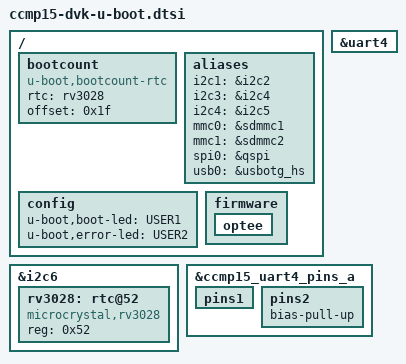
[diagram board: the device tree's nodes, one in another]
// SPDX-License-Identifier: GPL-2.0+ OR BSD-3-Clause
/*
 * Copyright (C) 2023-2025, Digi International Inc - All Rights Reserved
 */

#include "stm32mp15-u-boot.dtsi"

/ {
	bootcount {
		compatible = "u-boot,bootcount-rtc";
		rtc = <&rv3028>;
		offset = <0x1f>;
	};

	aliases {
		i2c1 = &i2c2;
		i2c3 = &i2c4;
		i2c4 = &i2c5;
		mmc0 = &sdmmc1;
		mmc1 = &sdmmc2;
		spi0 = &qspi;
		usb0 = &usbotg_hs;
	};

	config {
		u-boot,boot-led = "USER1";
		u-boot,error-led = "USER2";
	};

	firmware {
		optee {
			bootph-all;
		};
	};
};

&i2c6 {
	rv3028: rtc@52 {
		compatible = "microcrystal,rv3028";
		reg = <0x52>;
	};
};

&uart4 {
	bootph-all;
};

&ccmp15_uart4_pins_a {
	bootph-all;
	pins1 {
		bootph-all;
	};
	pins2 {
		bootph-all;
		/* pull-up on rx to avoid floating level */
		bias-pull-up;
	};
};
